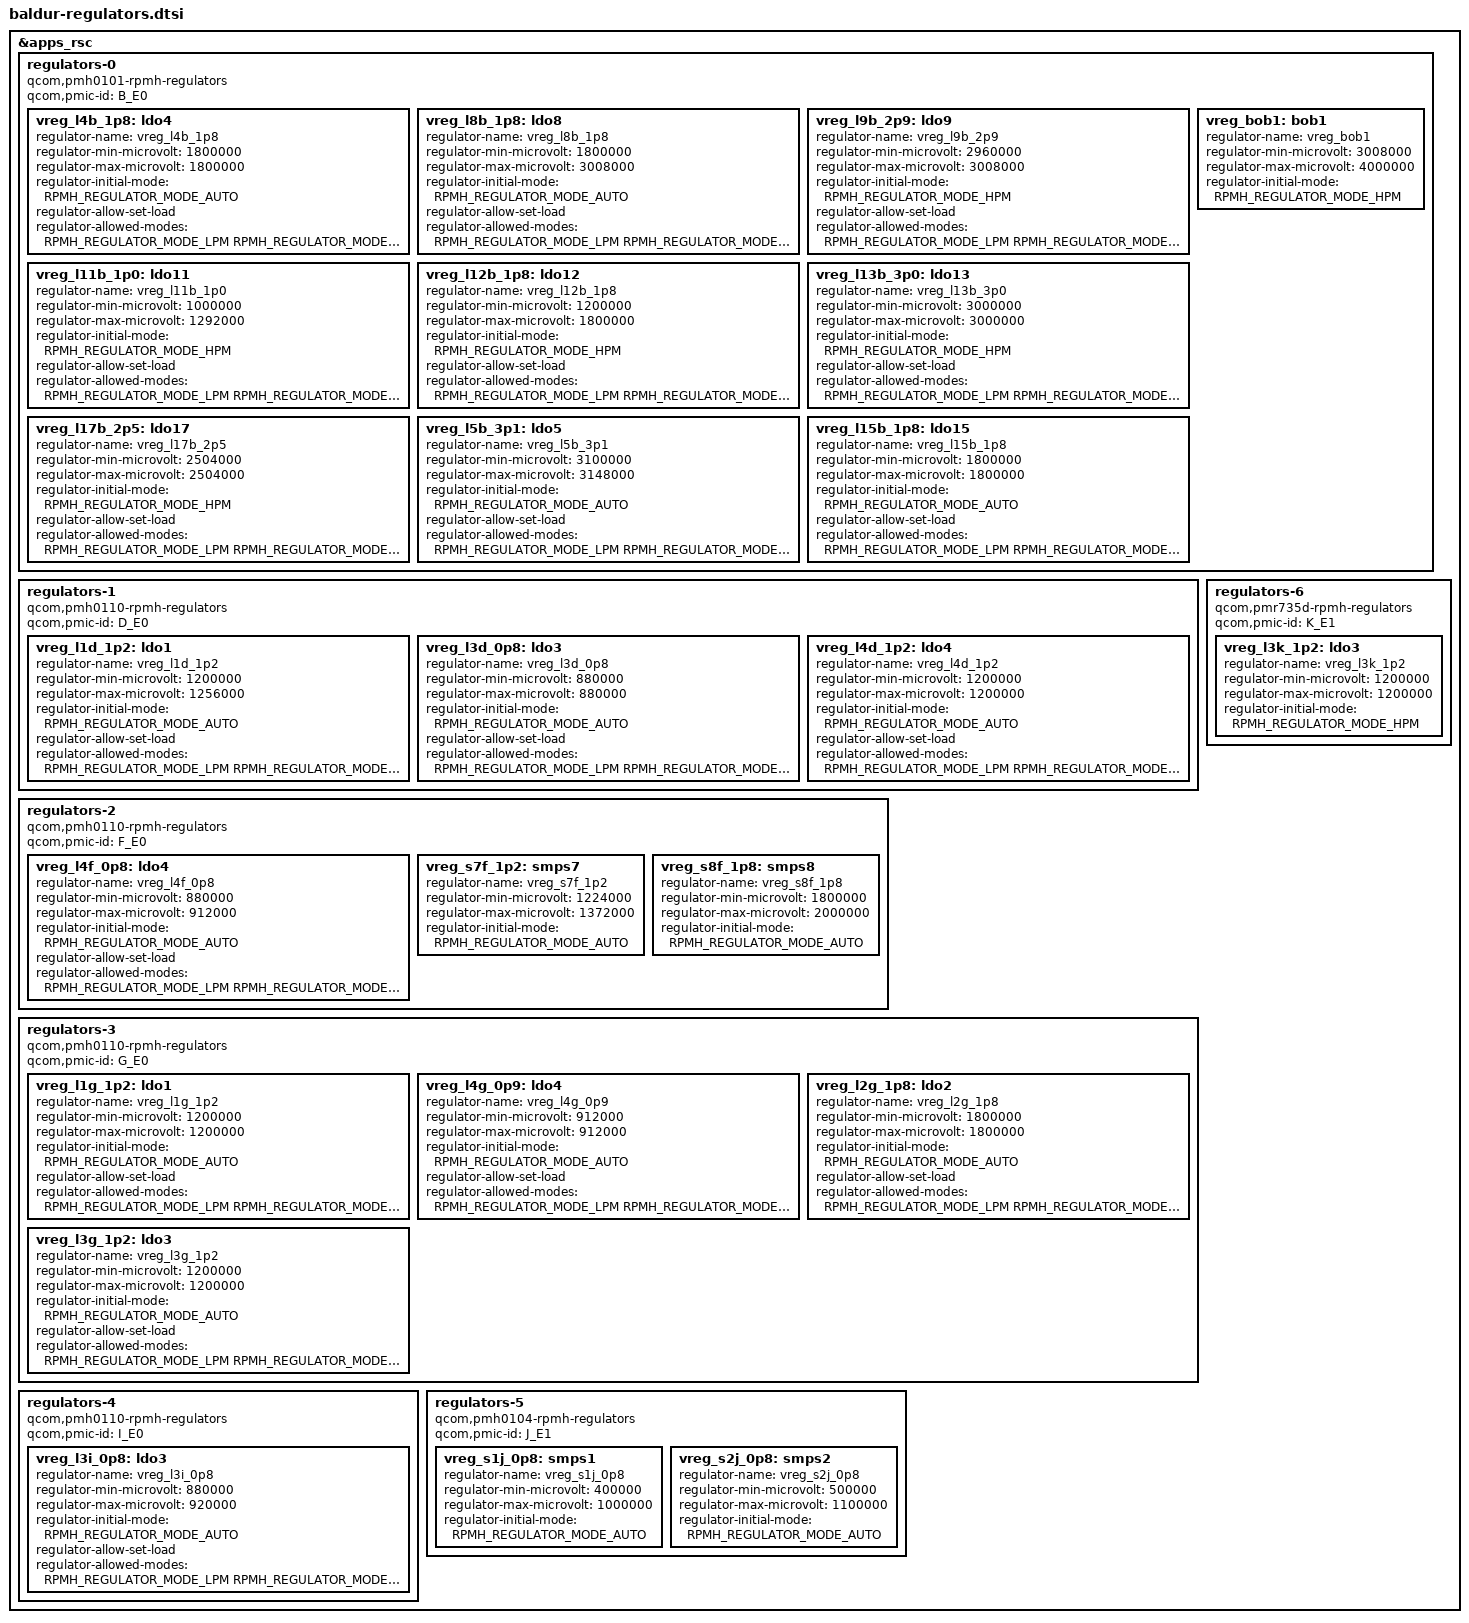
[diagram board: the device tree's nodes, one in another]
// SPDX-License-Identifier: BSD-3-Clause
/*
 * TB323FU ("baldur") PMIC rails.
 *
 * Only the rails something in this port actually consumes are here, not the
 * full PMIC complement. Every voltage was read out of this device's own ABL
 * devicetree (logs/2026-09-22-mainline-survey.txt), and the labels follow the
 * OnePlus 15 board DTS so the two can be compared line by line.
 *
 * Where the two boards differ, ours is used and the difference is noted. They
 * agree exactly on every storage rail; the panel rails are where our tablet
 * asks for a range and the phone pins a point, which is what a different panel
 * on the same PMIC looks like.
 *
 * Included by kaanapali-lenovo-baldur.dts. Needs
 * <dt-bindings/regulator/qcom,rpmh-regulator.h>.
 */

&apps_rsc {
	regulators-0 {
		compatible = "qcom,pmh0101-rpmh-regulators";
		qcom,pmic-id = "B_E0";

		/* touch AVDD switch */
		vreg_l4b_1p8: ldo4 {
			regulator-name = "vreg_l4b_1p8";
			regulator-min-microvolt = <1800000>;
			regulator-max-microvolt = <1800000>;
			/* 9-45: AUTO, as the MTP has it; HPM kept it in high power for good */
			regulator-initial-mode = <RPMH_REGULATOR_MODE_AUTO>;
			regulator-allow-set-load;
			regulator-allowed-modes = <RPMH_REGULATOR_MODE_LPM
						   RPMH_REGULATOR_MODE_AUTO
						   RPMH_REGULATOR_MODE_HPM>;
		};

		/* microSD level shifter / IO */
		vreg_l8b_1p8: ldo8 {
			regulator-name = "vreg_l8b_1p8";
			regulator-min-microvolt = <1800000>;
			regulator-max-microvolt = <3008000>;
			regulator-initial-mode = <RPMH_REGULATOR_MODE_AUTO>;
			regulator-allow-set-load;
			regulator-allowed-modes = <RPMH_REGULATOR_MODE_LPM
						   RPMH_REGULATOR_MODE_HPM>;
		};

		/* microSD card power */
		vreg_l9b_2p9: ldo9 {
			regulator-name = "vreg_l9b_2p9";
			regulator-min-microvolt = <2960000>;
			regulator-max-microvolt = <3008000>;
			regulator-initial-mode = <RPMH_REGULATOR_MODE_HPM>;
			regulator-allow-set-load;
			regulator-allowed-modes = <RPMH_REGULATOR_MODE_LPM
						   RPMH_REGULATOR_MODE_HPM>;
		};

		/*
		 * Panel core. The OnePlus 15 pins this at 1.2 V; ours is a
		 * 1.0-1.292 V range, which is the vendor leaving room for the
		 * panel's own voltage stepping.
		 */
		vreg_l11b_1p0: ldo11 {
			regulator-name = "vreg_l11b_1p0";
			regulator-min-microvolt = <1000000>;
			regulator-max-microvolt = <1292000>;
			regulator-initial-mode = <RPMH_REGULATOR_MODE_HPM>;
			regulator-allow-set-load;
			regulator-allowed-modes = <RPMH_REGULATOR_MODE_LPM
						   RPMH_REGULATOR_MODE_HPM>;
		};

		/* Panel VDDIO. OnePlus 15 pins this at 1.8 V; ours spans 1.2-1.8. */
		vreg_l12b_1p8: ldo12 {
			regulator-name = "vreg_l12b_1p8";
			regulator-min-microvolt = <1200000>;
			regulator-max-microvolt = <1800000>;
			regulator-initial-mode = <RPMH_REGULATOR_MODE_HPM>;
			regulator-allow-set-load;
			regulator-allowed-modes = <RPMH_REGULATOR_MODE_LPM
						   RPMH_REGULATOR_MODE_HPM>;
		};

		/* Panel VCI */
		vreg_l13b_3p0: ldo13 {
			regulator-name = "vreg_l13b_3p0";
			regulator-min-microvolt = <3000000>;
			regulator-max-microvolt = <3000000>;
			regulator-initial-mode = <RPMH_REGULATOR_MODE_HPM>;
			regulator-allow-set-load;
			regulator-allowed-modes = <RPMH_REGULATOR_MODE_LPM
						   RPMH_REGULATOR_MODE_HPM>;
		};

		/* UFS vcc */
		vreg_l17b_2p5: ldo17 {
			regulator-name = "vreg_l17b_2p5";
			regulator-min-microvolt = <2504000>;
			regulator-max-microvolt = <2504000>;
			regulator-initial-mode = <RPMH_REGULATOR_MODE_HPM>;
			regulator-allow-set-load;
			regulator-allowed-modes = <RPMH_REGULATOR_MODE_LPM
						   RPMH_REGULATOR_MODE_HPM>;
		};

		/* eUSB2 repeater 3.1 V (vendor pmh0101_l5 3.100-3.148 V) */
		vreg_l5b_3p1: ldo5 {
			regulator-name = "vreg_l5b_3p1";
			regulator-min-microvolt = <3100000>;
			regulator-max-microvolt = <3148000>;
			regulator-initial-mode = <RPMH_REGULATOR_MODE_AUTO>;
			regulator-allow-set-load;
			regulator-allowed-modes = <RPMH_REGULATOR_MODE_LPM
						   RPMH_REGULATOR_MODE_AUTO>;
		};

		/* eUSB2 repeater 1.8 V (vendor pmh0101_l15) */
		vreg_l15b_1p8: ldo15 {
			regulator-name = "vreg_l15b_1p8";
			regulator-min-microvolt = <1800000>;
			regulator-max-microvolt = <1800000>;
			regulator-initial-mode = <RPMH_REGULATOR_MODE_AUTO>;
			regulator-allow-set-load;
			regulator-allowed-modes = <RPMH_REGULATOR_MODE_LPM
						   RPMH_REGULATOR_MODE_AUTO>;
		};

		/* WCD9395 mic bias (vendor pmh0101_bob1, 3.008-4.0 V; 9-50) */
		vreg_bob1: bob1 {
			regulator-name = "vreg_bob1";
			regulator-min-microvolt = <3008000>;
			regulator-max-microvolt = <4000000>;
			regulator-initial-mode = <RPMH_REGULATOR_MODE_HPM>;
		};
	};

	regulators-1 {
		compatible = "qcom,pmh0110-rpmh-regulators";
		qcom,pmic-id = "D_E0";

		/* UFS PHY PLL, and the DSI controller's 1.2 V */
		vreg_l1d_1p2: ldo1 {
			regulator-name = "vreg_l1d_1p2";
			regulator-min-microvolt = <1200000>;
			regulator-max-microvolt = <1256000>;
			regulator-initial-mode = <RPMH_REGULATOR_MODE_AUTO>;
			regulator-allow-set-load;
			regulator-allowed-modes = <RPMH_REGULATOR_MODE_LPM
						   RPMH_REGULATOR_MODE_HPM>;
		};

		/* DSI PHY 0.9 V */
		vreg_l3d_0p8: ldo3 {
			regulator-name = "vreg_l3d_0p8";
			regulator-min-microvolt = <880000>;
			regulator-max-microvolt = <880000>;
			regulator-initial-mode = <RPMH_REGULATOR_MODE_AUTO>;
			regulator-allow-set-load;
			regulator-allowed-modes = <RPMH_REGULATOR_MODE_LPM
						   RPMH_REGULATOR_MODE_HPM>;
		};

		/* UFS vccq */
		vreg_l4d_1p2: ldo4 {
			regulator-name = "vreg_l4d_1p2";
			regulator-min-microvolt = <1200000>;
			regulator-max-microvolt = <1200000>;
			regulator-initial-mode = <RPMH_REGULATOR_MODE_AUTO>;
			regulator-allow-set-load;
			regulator-allowed-modes = <RPMH_REGULATOR_MODE_LPM
						   RPMH_REGULATOR_MODE_HPM>;
		};
	};

	regulators-2 {
		compatible = "qcom,pmh0110-rpmh-regulators";
		qcom,pmic-id = "F_E0";

		/* USB eUSB2 PHY core (vendor pmh0110_f_l4 0.880-0.912 V) */
		vreg_l4f_0p8: ldo4 {
			regulator-name = "vreg_l4f_0p8";
			regulator-min-microvolt = <880000>;
			regulator-max-microvolt = <912000>;
			regulator-initial-mode = <RPMH_REGULATOR_MODE_AUTO>;
			regulator-allow-set-load;
			regulator-allowed-modes = <RPMH_REGULATOR_MODE_LPM
						   RPMH_REGULATOR_MODE_AUTO>;
		};

		/*
		 * WCN7860 RFA 1.3 V (vendor pmh0110_f_s7 1.224-1.372 V). Like S8F,
		 * S1J and S2J it is in the vendor's qcom,vreg_pdc_map: the chip's own
		 * clock request raises it, and Android's vote sits at the minimum.
		 */
		vreg_s7f_1p2: smps7 {
			regulator-name = "vreg_s7f_1p2";
			regulator-min-microvolt = <1224000>;
			regulator-max-microvolt = <1372000>;
			/*
			 * 9-45: AUTO (PFM when light), not HPM (always PWM): the WCN
			 * rails sat in high power even with Wi-Fi idle. The vendor
			 * lets the chip raise them through the PDC instead.
			 */
			regulator-initial-mode = <RPMH_REGULATOR_MODE_AUTO>;
		};

		/* WCN7860 RFA 1.9 V (vendor pmh0110_f_s8 1.8-2.0 V) */
		vreg_s8f_1p8: smps8 {
			regulator-name = "vreg_s8f_1p8";
			regulator-min-microvolt = <1800000>;
			regulator-max-microvolt = <2000000>;
			/*
			 * 9-45: AUTO (PFM when light), not HPM (always PWM): the WCN
			 * rails sat in high power even with Wi-Fi idle. The vendor
			 * lets the chip raise them through the PDC instead.
			 */
			regulator-initial-mode = <RPMH_REGULATOR_MODE_AUTO>;
		};
	};

	regulators-3 {
		compatible = "qcom,pmh0110-rpmh-regulators";
		qcom,pmic-id = "G_E0";

		/* WCD9395 vdd-px (vendor pmh0110_g_l1 1.2 V; 9-50) */
		vreg_l1g_1p2: ldo1 {
			regulator-name = "vreg_l1g_1p2";
			regulator-min-microvolt = <1200000>;
			regulator-max-microvolt = <1200000>;
			regulator-initial-mode = <RPMH_REGULATOR_MODE_AUTO>;
			regulator-allow-set-load;
			regulator-allowed-modes = <RPMH_REGULATOR_MODE_LPM
						   RPMH_REGULATOR_MODE_AUTO>;
		};

		/* UFS PHY */
		vreg_l4g_0p9: ldo4 {
			regulator-name = "vreg_l4g_0p9";
			regulator-min-microvolt = <912000>;
			regulator-max-microvolt = <912000>;
			regulator-initial-mode = <RPMH_REGULATOR_MODE_AUTO>;
			regulator-allow-set-load;
			regulator-allowed-modes = <RPMH_REGULATOR_MODE_LPM
						   RPMH_REGULATOR_MODE_HPM>;
		};

		/* WCN7860 I/O (vendor pmh0110_g_l2 1.8 V, "vdd-wlan-aon") */
		vreg_l2g_1p8: ldo2 {
			regulator-name = "vreg_l2g_1p8";
			regulator-min-microvolt = <1800000>;
			regulator-max-microvolt = <1800000>;
			regulator-initial-mode = <RPMH_REGULATOR_MODE_AUTO>;
			regulator-allow-set-load;
			regulator-allowed-modes = <RPMH_REGULATOR_MODE_LPM
						   RPMH_REGULATOR_MODE_AUTO>;
		};

		/* WCN7860 I/O 1.2 V (vendor pmh0110_g_l3, "vdd-wlan-io12") */
		vreg_l3g_1p2: ldo3 {
			regulator-name = "vreg_l3g_1p2";
			regulator-min-microvolt = <1200000>;
			regulator-max-microvolt = <1200000>;
			regulator-initial-mode = <RPMH_REGULATOR_MODE_AUTO>;
			regulator-allow-set-load;
			regulator-allowed-modes = <RPMH_REGULATOR_MODE_LPM
						   RPMH_REGULATOR_MODE_AUTO>;
		};
	};

	regulators-4 {
		compatible = "qcom,pmh0110-rpmh-regulators";
		qcom,pmic-id = "I_E0";

		/* PCIe0 PHY (OnePlus 15 / MTP value; the vendor DT has no PHY rail) */
		vreg_l3i_0p8: ldo3 {
			regulator-name = "vreg_l3i_0p8";
			regulator-min-microvolt = <880000>;
			regulator-max-microvolt = <920000>;
			regulator-initial-mode = <RPMH_REGULATOR_MODE_AUTO>;
			regulator-allow-set-load;
			regulator-allowed-modes = <RPMH_REGULATOR_MODE_LPM
						   RPMH_REGULATOR_MODE_AUTO>;
		};
	};

	regulators-5 {
		compatible = "qcom,pmh0104-rpmh-regulators";
		qcom,pmic-id = "J_E1";

		/* WCN7860 WLCX (vendor pmh0104_s1 0.4-1.0 V, "vdd-wlan-cx") */
		vreg_s1j_0p8: smps1 {
			regulator-name = "vreg_s1j_0p8";
			regulator-min-microvolt = <400000>;
			regulator-max-microvolt = <1000000>;
			/*
			 * 9-45: AUTO (PFM when light), not HPM (always PWM): the WCN
			 * rails sat in high power even with Wi-Fi idle. The vendor
			 * lets the chip raise them through the PDC instead.
			 */
			regulator-initial-mode = <RPMH_REGULATOR_MODE_AUTO>;
		};

		/* WCN7860 AON/WLMX/RFA 0.9 V (vendor pmh0104_s2 0.5-1.1 V, "vdd-wlan-dig") */
		vreg_s2j_0p8: smps2 {
			regulator-name = "vreg_s2j_0p8";
			regulator-min-microvolt = <500000>;
			regulator-max-microvolt = <1100000>;
			/*
			 * 9-45: AUTO (PFM when light), not HPM (always PWM): the WCN
			 * rails sat in high power even with Wi-Fi idle. The vendor
			 * lets the chip raise them through the PDC instead.
			 */
			regulator-initial-mode = <RPMH_REGULATOR_MODE_AUTO>;
		};
	};

	regulators-6 {
		compatible = "qcom,pmr735d-rpmh-regulators";
		qcom,pmic-id = "K_E1";

		/*
		 * WCN7860 "vdd-wlan-ant-share" (vendor pmr735d_l3 1.2 V, 25 uA),
		 * which the vendor cnss turns on second, before WLAN_EN. The WCN7850
		 * power sequencer has no input for it; baldur-wifi.dtsi keeps it on.
		 */
		vreg_l3k_1p2: ldo3 {
			regulator-name = "vreg_l3k_1p2";
			regulator-min-microvolt = <1200000>;
			regulator-max-microvolt = <1200000>;
			regulator-initial-mode = <RPMH_REGULATOR_MODE_HPM>;
		};
	};
};
